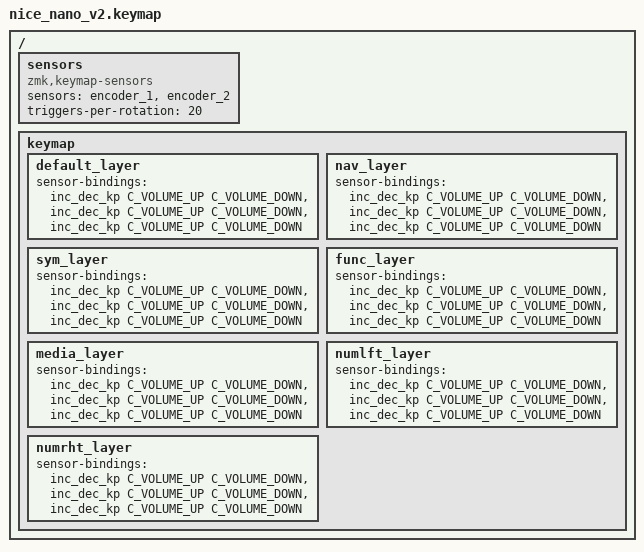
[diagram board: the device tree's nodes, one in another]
/ {
    sensors {
        compatible = "zmk,keymap-sensors";
        sensors = <&encoder_1 &encoder_2>;
        triggers-per-rotation = <20>;
    };
    
    keymap {
        default_layer {
            sensor-bindings = <&inc_dec_kp C_VOLUME_UP C_VOLUME_DOWN &inc_dec_kp C_VOLUME_UP C_VOLUME_DOWN &inc_dec_kp C_VOLUME_UP C_VOLUME_DOWN>;
        };
        nav_layer {
            sensor-bindings = <&inc_dec_kp C_VOLUME_UP C_VOLUME_DOWN &inc_dec_kp C_VOLUME_UP C_VOLUME_DOWN &inc_dec_kp C_VOLUME_UP C_VOLUME_DOWN>;
        };
        sym_layer {
            sensor-bindings = <&inc_dec_kp C_VOLUME_UP C_VOLUME_DOWN &inc_dec_kp C_VOLUME_UP C_VOLUME_DOWN &inc_dec_kp C_VOLUME_UP C_VOLUME_DOWN>;
        };
        func_layer {
            sensor-bindings = <&inc_dec_kp C_VOLUME_UP C_VOLUME_DOWN &inc_dec_kp C_VOLUME_UP C_VOLUME_DOWN &inc_dec_kp C_VOLUME_UP C_VOLUME_DOWN>;
        };
        media_layer {
            sensor-bindings = <&inc_dec_kp C_VOLUME_UP C_VOLUME_DOWN &inc_dec_kp C_VOLUME_UP C_VOLUME_DOWN &inc_dec_kp C_VOLUME_UP C_VOLUME_DOWN>;
        };
        numlft_layer {
            sensor-bindings = <&inc_dec_kp C_VOLUME_UP C_VOLUME_DOWN &inc_dec_kp C_VOLUME_UP C_VOLUME_DOWN &inc_dec_kp C_VOLUME_UP C_VOLUME_DOWN>;
        };
        numrht_layer {
            sensor-bindings = <&inc_dec_kp C_VOLUME_UP C_VOLUME_DOWN &inc_dec_kp C_VOLUME_UP C_VOLUME_DOWN &inc_dec_kp C_VOLUME_UP C_VOLUME_DOWN>;
        };
    }
}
